# CIM register map
Vendor: Texas Instruments
Peripheral module from a debugger description file (folder ucd3138).
Registers are 32-bit, read-write, no defined reset value unless marked. A register's access mark holds for its fields unless they carry their own. Offsets are as the file gives them; lines under a group give offsets from that group; [hi:lo] are bit positions; {n}, {i} and the like mark numbered series; 'fields as' and 'values as' point back to an identical list; <NAME> marks a mode.

## CIM
0x00 IRQIVEC access not given — IRQ Index Offset Vector Register
  [7:0] IRQIVEC ro — Index vector
0x04 FIQIVEC access not given — FIQ Index Offset Vector Register
  [7:0] FIQIVEC ro — Index vector
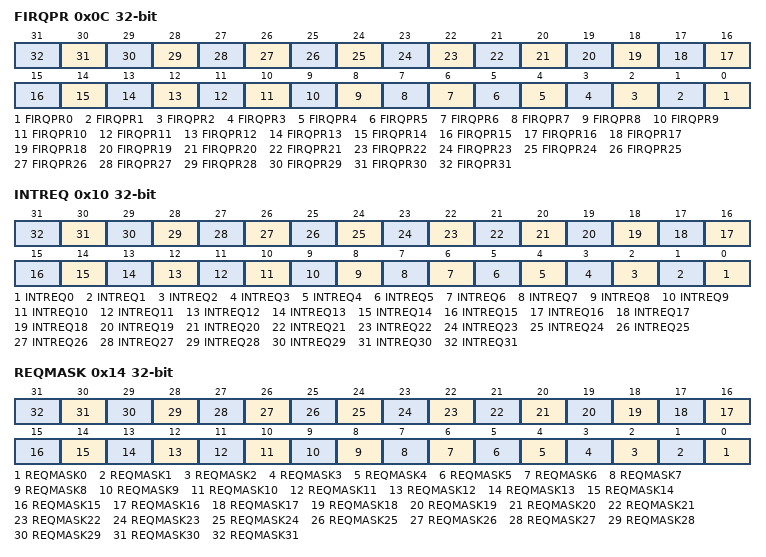
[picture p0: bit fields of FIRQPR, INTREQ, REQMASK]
0x0C FIRQPR — FIQ/IRQ Program Control Register
  [n] FIRQPR{n} (n=0..31) — Interrupt {n}
0x10 INTREQ — Pending Interrupt Read Location
  [n] INTREQ{n} (n=0..31) — Interrupt {n}
0x14 REQMASK — Interrupt Mask Register
  [n] REQMASK{n} (n=0..31) — Interrupt {n}
